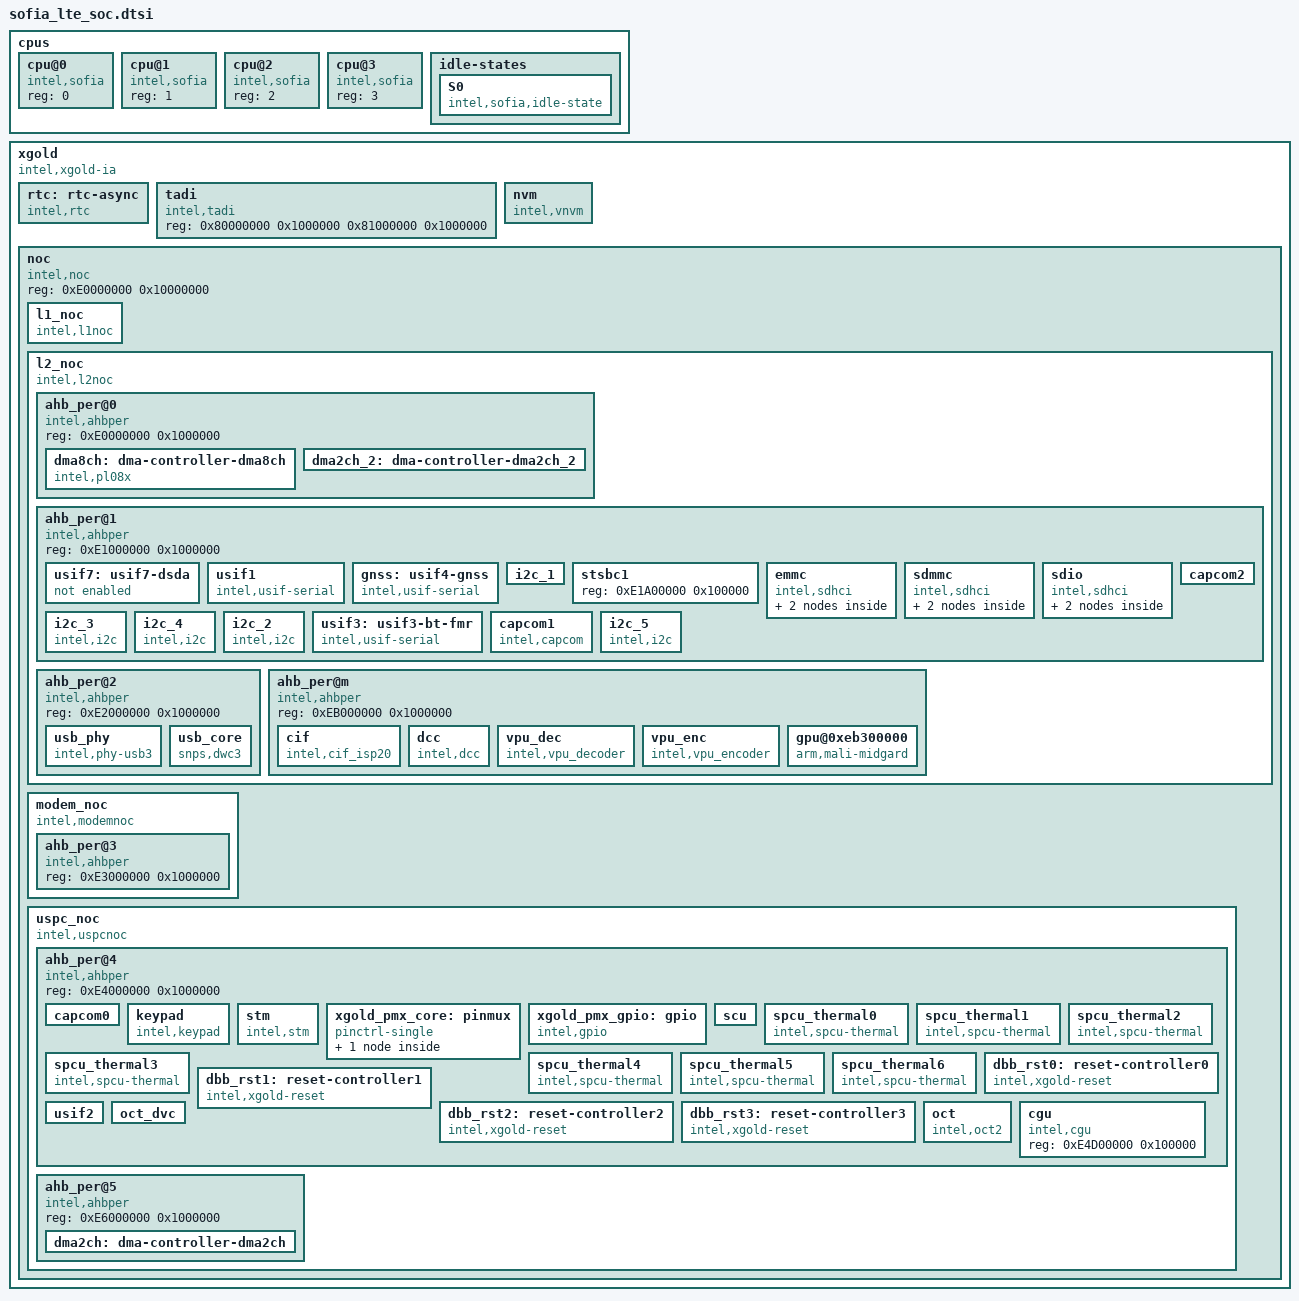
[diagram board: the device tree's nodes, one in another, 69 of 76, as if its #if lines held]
#define PREFERRED_LOCAL_APIC_USE
#define BOOST_LOCAL_APIC_USE
	cpus {
		#address-cells = <1>;
		#size-cells = <0>;
		cpu@0 {
			device_type = "cpu";
			compatible = "intel,sofia";
			reg = <0>;
		};

		cpu@1 {
			device_type = "cpu";
			compatible = "intel,sofia";
#ifdef CONFIG_X86_INTEL_SOFIA
			reg = <1>;
#else
			reg = <2>;
#endif
		};

		cpu@2 {
			device_type = "cpu";
			compatible = "intel,sofia";
			reg = <2>;
		};
		cpu@3 {
			device_type = "cpu";
			compatible = "intel,sofia";
			reg = <3>;
		};

		 idle-states {

#define CPUIDLE_FLAG_TIME_VALID	(0x01) /* is residency time measurable? */
#define CPUIDLE_FLAG_COUPLED	(0x02) /* state applies to multiple cpus */
#define CPUIDLE_FLAG_TIMER_STOP (0x04)  /* timer is stopped on this state */

			S0 {
				compatible = "intel,sofia,idle-state";
				desc = "WFE";
				power-usage = <100>;
				exit-latency = <100>;
				target-residency= <100>;
				flags = <1>;	/* CPUIDLE_FLAG_TIME_VALID */
				vmm-id = <0>;
			};
		};
	};

	xgold {
		compatible = "intel,xgold-ia", "intel,soc";
		intel,platform-dev = "uspcnoc", "noc", "l1noc", "l2noc", "modemnoc", "ahbper";
		device_type = "soc";
		#address-cells = <1>;
		#size-cells = <1>;
		ranges;
		interrupt-parent = <&pic>;
		intel,scu-phys = < &scu >;
		intel,chipid = <0x60 0x8 0x8>;
		intel,rev = <0x60 0x0 0x8>;
		intel,machine = "sofia_lte_soc-es1-svb";
#ifndef PSV_DEEP_SLEEP
		intel,nodeepsleep;
#endif
#ifndef SOFIALTE_ES2
		intel,nosteal;
#endif

		#include "xgold/sofia_lte_soc/irq-apic.dtsi"
#ifdef SOFIALTE_ES2
		#include "xgold/sofia_lte_soc/pm.dtsi"
#else
		#include "xgold/sofia_lte_soc/pm-es1.dtsi"
#endif

		/*
		 * WARNING:
		 * rtc node name must be "rtc" as it used to
		 * register wallclock callbacks during early boot
		 * To discard "rtc" from being used in wallclock
		 * callbacks, rename this node like rtc-nowc
		 */
		rtc:rtc-async {
			compatible = "intel,rtc";
			#address-cells = <0>;
			#interrupt-cells = < 1 >;
			interrupts = <0 1>;
			interrupt-names = "alarm", "completion";
			interrupt-parent = <&rtc>;
			interrupt-map = < 0 &hirq HIRQ_PMIC_SYS_ALARM IRQ_TYPE_DEFAULT
					  1 &hirq HIRQ_PMIC_RTC_STATUS IRQ_TYPE_DEFAULT >;
			intel,async = < 1 >;
			intel,base_year = < 2000 >;
		};

		tadi:tadi {
			compatible = "intel,tadi";
			#address-cells = < 0 >;
			reg = <0x80000000 0x1000000
					0x81000000 0x1000000>;
			reg-names = "trace-port", "trace-port-1";
		};
               nvm:nvm {
                       compatible = "intel,vnvm";
                       #address-cells = < 0 >;
                       intel,nb-part = < 1 >;
                       intel,part-names =
                       "/dev/block/platform/soc0/e0000000.noc/by-name/ImcPartID022";
               };

		noc {
			compatible = "intel,noc";
			#address-cells = <1>;
			#size-cells = <1>;
			ranges;
			reg = <0xE0000000 0x10000000>;

			l1_noc {
				compatible = "intel,l1noc";
				#address-cells = <1>;
				#size-cells = <1>;
				ranges;
				reg = <0xE9010000 0x4000>;

				clocks = < &clk_L1_NoC >;
				clock,rate = <400000000>;
				interrupts = < NOC_ERR_APS_L1 IRQ_TYPE_DEFAULT >, < NOC_STATALARM IRQ_TYPE_DEFAULT >;
				interrupt-names = "error", "stat_alarm";
				probe,nr = < 5 >;
				filter,nr = < 4 >;
				counter,nr = < 2 >;

				probe,offset = < 0x2000 >;

#ifdef SOFIALTE_ES2
				probe,portsel,0 = "CPU_MMIO", "CPU_PMI";
				probe,portsel,1 = "EMIC0", "EMIC1", "EMIC2";
				probe,portsel,2 = "CIF", "GPU";
				probe,portsel,3 = "DCC1", "DCC2", "VEC", "VED";
				probe,portsel,4 = "LMU";

				stat,0 = "CPU_PMI";
				stat,1 = "CPU_MMIO";
				stat,2 = "GPU";
				stat,3 = "DCC2";
				stat,4 = "VED";
				stat,5 = "VEC";
				stat,6 = "EMIC0";
				stat,7 = "EMIC1";
				stat,8 = "EMIC2";
				stat,9 = "CIF";

				intel,qos-configs = "DCC2", "GPU", "CPU1";

				intel,GPU-qos-settings = <
					0x3588 0x0      /* prio */
					0x358C 0x1      /* mode */
					0x3590 0xFFF    /* bandwidth */
					0x3594 0x3FF     /* saturation */
					0x3598 0x5>;    /* ExtCtrl */

				intel,DCC2-qos-settings = <
					0x3688 0xE      /* prio */
					0x368C 0x3      /* mode */
					0x3690 0x9F     /* bandwidth */
					0x3694 0x90     /* saturation */
					0x3698 0x5>;    /* ExtCtrl */

				intel,CPU1-qos-owner;
				intel,CPU1-qos-settings = <
					0x3708 0xF      /* prio */
					0x370C 0x0      /* mode */
					0x3710 0xFFF    /* bandwidth */
					0x3714 0x0     /* saturation */
					0x3718 0x5>;    /* ExtCtrl */

                                #include "xgold/sofia_lte_soc/NoC-es2.0.dtsi"
#else
				probe,portsel,0 = "CPU_PMI", "CPU_MMIO";
				probe,portsel,1 = "EMIC";
				probe,portsel,2 = "CIF", "GPU";
				probe,portsel,3 = "DCC1", "DCC2", "VPU";
				probe,portsel,4 = "LMU";

				stat,0 = "CPU_PMI";
				stat,1 = "CPU_MMIO";
				stat,2 = "GPU";
				stat,3 = "DCC2";
				stat,4 = "EMIC";

				intel,qos-configs = "DCC2", "GPU";
				intel,GPU-qos-owner;
				intel,GPU-qos-settings = <
					0x358C 0x1      /* GPU mode limiter */
					0x3588 0x0      /* GPU rw/wr prio 0/0 */
					0x3590 0x120    /* GPU bandwidth */
					0x3594 0x90     /* GPU saturation */
					0x3598 0x5>;    /* GPU QoSEn */

				intel,DCC2-qos-owner;
				intel,DCC2-qos-settings = <
					0x3608 0xE      /* DCC2 prio 2/3 */
					0x360C 0x3      /* DCC2 mode regulator*/
					0x3610 0x9F     /* DCC2 bandwidth */
					0x3614 0x90     /* DCC2 saturation */
					0x3618 0x5>;    /* DCC2 QoSEn */

                                #include "xgold/sofia_lte_soc/NoC.dtsi"
#endif
			};

			l2_noc {
				compatible = "intel,l2noc";
				#address-cells = <1>;
				#size-cells = <1>;
				ranges;
				reg = <0xE9014000 0x4000>;

				clocks = < &clk_L2_NoC >;
				interrupts = < NOC_ERR_APS_L2 IRQ_TYPE_DEFAULT >, < NOC_STATALARM IRQ_TYPE_DEFAULT >;
				interrupt-names = "error", "stat_alarm";
				clock,rate = <200000000>;
				probe,nr = < 5 >;
				filter,nr = < 4 >;
				counter,nr = < 2 >;

				probe,offset = < 0x2000 >;

				probe,portsel,0 = "DMA8C_1";
				probe,portsel,1 = "USB30";
				probe,portsel,2 = "SDIO", "SDMMC", "eMMC";
				probe,portsel,3 = "DMA2C_L2_1", "DMA2C_L2_2";
				probe,portsel,4 = "DMA8C_2";

				stat,0 = "eMMC";
				stat,1 = "SDIO";
				stat,2 = "SDMMC";
				stat,3 = "USB30";

				#include "xgold/sofia_lte_soc/NoC.dtsi"

				ahb_per@0 {
					compatible = "intel,ahbper";
					#address-cells = <1>;
					#size-cells = <1>;
					ranges;
					reg = <0xE0000000 0x1000000>;

					dma8ch:dma-controller-dma8ch {
						compatible = "intel,pl08x";
						reg = <0xE0100000 0x100000>;
						reg-names = "register";
						intel,dma-pl08x,buses =  < 1 1 >;
						intel,dma-pl08x,memcpy = < 3 3 2 2 1 1 1 >;
						intel,dma-pl08x,periphid = < 0x00041080 >;
						intel,mux-base = < &scu >;
						interrupts = < DMA1_ERR_INT IRQ_TYPE_DEFAULT >, < DMA1_CH0_7_INT IRQ_TYPE_DEFAULT >;
						interrupt-names = "err","chx";
						clocks = <&clk_L1_NoC>, <&clk_ahb_per0_dmac8>;
						clock-names = "clk_master1", "apb_pclk";

						#dma-cells = <1>;
						dma-channels = <15>;
						dma-requests = <21>;

						pm,class-name = "dma8ch_class";
						pm,user-name = "dmac_8ch";
						pm,state-D0 = "high_perf";
						pm,state-D3 = "disable";

						resets = < &dbb_rst2 0 >;
						reset-names = "dma";

						#include "xgold/sofia_lte_soc/dma.dtsi"
					};

					dma2ch_2:dma-controller-dma2ch_2 {
						reg = <0xE0400000 0x100000>;
						resets = < &dbb_rst2 12 >;
						reset-names = "dma2ch";
					};
				};

				ahb_per@1 {
					compatible = "intel,ahbper";
					#address-cells = <1>;
					#size-cells = <1>;
					ranges;
					reg = <0xE1000000 0x1000000>;

					usif7:usif7-dsda {
						compatible = "not enabled";
						reg = <0xE1000000 0x100000>;
						#address-cells = < 0 >;
						interrupts = < 0 >;
						interrupt-parent = <&usif7>;
						#interrupt-cells = < 1 >;
						interrupt-map = <
							0 &pic USIF7_INT IRQ_TYPE_DEFAULT
						>;
						interrupt-names = "usif-int";
						clocks = <&clk_usif7>, <&clk_ahb_per1>;
						clock-names = "kernel", "register";
						resets = < &dbb_rst2 29 >;
						reset-names = "usif";
					};

					usif1:usif1 {
						compatible = "intel,usif-serial";
						reg = <0xE1100000 0x100000>;
						#address-cells = < 0 >;
						intel,serial-port = < 0 >;
						wakeup-source;
						interrupts = < 0 1 >;
						interrupt-parent = <&usif1>;
						#interrupt-cells = < 1 >;
						interrupt-map = <
							0 &pic USIF1_INT IRQ_TYPE_DEFAULT
							1 &eint EINT_USIF1_WK XGOLD_IRQ_TYPE_EDGE_RISING
						>;
						interrupt-names = "usif-int", "wk_int";
						clocks = <&clk_usif1>, <&clk_ahb_per1>;
						clock-names = "kernel", "register";

						pm,class-name = "usif_class";
						pm,user-name = "usif1";
						pm,state-D0 = "enable_104M_hperf";
						pm,state-D3 = "disable";

						pm,runtime = "disable";
						pm,debug_rpm = "disable";
					};


					gnss:usif4-gnss {
						compatible = "intel,usif-serial";
						reg = <0xE1200000 0x100000>;
						#address-cells = < 0 >;
						intel,serial-port = < 1 >;
						wakeup-source;
						intel,usif-debug;
						intel,modem_poll_timeout = < 5 >;
						interrupts = < 0 1 >;
						interrupt-parent = <&gnss>;
						#interrupt-cells = < 1 >;
						interrupt-map = <
							0 &pic USIF4 IRQ_TYPE_DEFAULT
							1 &eint EINT_EXI15 XGOLD_IRQ_TYPE_EDGE_FALLING
						>;
						interrupt-names = "usif-int", "wk_int";
						clocks = <&clk_usif_gnss>, <&clk_ahb_per1>;
						clock-names = "kernel", "register";

						pm,class-name = "usif_class";
						pm,user-name = "usif4";
						pm,state-D0 = "enable_104M_hperf";
						pm,state-D3 = "disable";

						pm,runtime = "enable";
						pm,rpm_suspend_delay = < 15 >;
						pm,auto_suspend_enable = "enable";
						pm,gen_uevent;
					};

					i2c_1:i2c_1 {
						/* compatible = "intel,i2c"; */
						#size-cells = <1>;
						#address-cells = <0>;
						reg = <0xE1300000 0x100000>;
						clocks = <&clk_i2c1>, <&clk_ahb_per1>;
						clock-names = "clk_kernel", "clk_ahb";
						interrupts = < I2C1_INT IRQ_TYPE_DEFAULT >;
						resets = < &dbb_rst2 7 >;
						reset-names = "i2c";

						intel,i2c,b400 = < 1 54 13 0 >;
						intel,i2c,b100 = < 1 256 0 0 >;

						pm,class-name = "i2c_class";
						pm,user-name = "i2c1";
						pm,state-D0 = "enable";
						pm,state-D3 = "disable";
					};

					stsbc1:stsbc1 {
						reg = <0xE1A00000 0x100000 >;
					};

					emmc:emmc {
						compatible = "intel,sdhci";
						reg = <0xE1D00000 0x100000>;
						clocks = <&clk_emmc_kernel>, <&clk_ahb_per1>;
						clock-names = "clk_core", "clk_ahb";
						interrupts = < EMMC_INT IRQ_TYPE_DEFAULT >;
						/*setted by bootcode, capabilities register not correct*/
						/*vmmc-supply = <&vemmc>;*/
						/*vqmmc-supply = <&vdd1>;*/
#ifdef SOFIALTE_ES2
						intel,max_clock = <104000000>;
#else
						intel,max_clock = <52000000>;
#endif
						intel,min_clock = <203125>;
						intel,tap-hwbase = < &stsbc1 >;
						intel,tap_reg = < 0x40000 >;
						/* QUIRK_CAP_CLOCK_BASE_BROKEN: bit 25 + QUIRKS2_HOST_PRESET_VALUE_BROKEN: bit 3 + LED_BROKEN: bit 14*/
						intel,quirks = < 0x2000000 0x4008 >;
						bus-width = < 8 >;
						non-removable;
						intel,io-access-guest;
						pm_ctrl{
							pm,class-name = "mmcsd_volt_class";
							pm,user-name = "vemmc_volt";
							pm,state-D0 = "high_perf";
							pm,state-D0i2 = "mid_perf";
							pm,state-D3 = "disable";
						};
						clock_ctrl{
							pm,class-name = "mmcsd_clk_class";
							pm,user-name = "emmc_clk";
							pm,state-D0 = "mid_perf";
							pm,state-D0i2 = "mid_perf";
							pm,state-D3 = "disable";
						};


					};

					sdmmc:sdmmc {
						compatible = "intel,sdhci";
						#address-cells = < 0 >;
						reg = <0xE1400000 0x100000>;
					        clocks = <&clk_sdmmc_kernel>, <&clk_ahb_per1_sdmmc>;
						clock-names = "clk_core", "clk_ahb";
						interrupts = <0 1>;
						interrupt-parent = <&sdmmc>;
						#interrupt-cells = < 1 >;
						interrupt-map = <
							0 &pic SDMMC_INT IRQ_TYPE_DEFAULT
							1 &eint EINT_SDMMC_DETECT XGOLD_IRQ_TYPE_EDGE_BOTH >;
						interrupt-names = "host";
						resets = < &dbb_rst2 2 >;
						reset-names = "sdmmc";
						vqmmc-supply = <&vsdmmc>;
						intel,max_clock = <96000000>;
						intel,min_clock = <203125>;
						intel,tap-hwbase = < &stsbc1 >;
						intel,tap_reg = < 0x80000 >;
						intel,corecfg_reg = < 0x80008 >;
						intel,corecfg_val = < 0x0074C72>;
						/* BROKEN_CARD_DETECTION: bit15/
						/* QUIRK2_HOST_PRESET_VAL_BROKEN: bit3 */
						/* QUIRK2_POWER_CONTROL_BUG: bit15 */
						/* QUIRK2_HOST_EXEC_TUNING_WA: bit23 */
#ifdef SOFIALTE_ES2
						intel,quirks = < 0x0 0x80c008 >;
#else
						intel,quirks = < 0x8000 0xc008 >;
#endif
						intel,fixup = <0x1>;
						intel,io-access-guest;
						pm_ctrl{
							pm,class-name = "mmcsd_volt_class";
							pm,user-name = "sdmmc1_volt";
							pm,state-D0 = "high_perf";
							pm,state-D0i2 = "mid_perf";
							pm,state-D3 = "disable";
						};
						clock_ctrl{
							pm,class-name = "mmcsd_clk_class";
							pm,user-name = "sdmmc1_clk";
							pm,state-D0 = "mid_perf";
							pm,state-D0i2 = "mid_perf";
							pm,state-D3 = "disable";
						};

					};
					sdio:sdio {
						compatible = "intel,sdhci";
						#address-cells = < 0 >;
						reg = <0xE1700000 0x100000>;
					        clocks = <&clk_sdio_kernel>, <&clk_ahb_per1_sdio>;
						clock-names = "clk_core", "clk_ahb";
						interrupts = < SDIO_INT IRQ_TYPE_DEFAULT >;
						resets = < &dbb_rst2 3 >;
						reset-names = "sdio";
						vmmc-supply = <&wlan_ldo>;
						intel,max_clock = <200000000>;
						intel,min_clock = <203125>;
						intel,tap-hwbase = < &stsbc1 >;
						intel,tap_reg = < 0xc0000 >;
						intel,tap_reg2 = < 0xc0008 >;   /* used for feedback clock control */
						intel,corecfg_reg = < 0xc0004 0xc0008 0xc0020>;
#ifdef SOFIALTE_ES2
						/*
						 * XGOLD_DEFAULT_REGS_FIXUP	(1 << 0)
						 */
						intel,fixup = <0x1>;
						intel,corecfg_val = < 0xfe1ada20 0x0074F76 0x00001e>;
						intel,rpm_enabled = <1>;
#else
						intel,corecfg_val = < 0xfe1ada20 0x0074176 0x0000FF>;
#endif
						non-removable;
						/* QUIRK1_HOST_CLOCK_BASE_BROKEN: bit25 */
						/* QUIRK2_HOST_PRESET_VAL_BROKEN: bit3 */
						/* QUIRK2_WA_LNP: bit22 */
						/* QUIRK2_HOST_EXEC_TUNING_WA: bit23 */
						intel,quirks = < 0x2000000 0xc00008 >;
						intel,io-access-guest;
						keep-power-in-suspend;
						cap-power-off-card;
						pm_ctrl{
							pm,class-name = "mmcsd_volt_class";
							pm,user-name = "sdio_volt";
							pm,state-D0 = "high_perf";
							pm,state-D0i2 = "mid_perf";
							pm,state-D3 = "disable";
						};
						clock_ctrl{
							pm,class-name = "mmcsd_clk_class";
							pm,user-name = "sdio_clk";
							pm,state-D0 = "high_perf";
							pm,state-D0i2 = "high_perf";
							pm,state-D3 = "disable";
						};

					};


					i2c_3:i2c_3 {
						compatible = "intel,i2c";
						#size-cells = <1>;
						#address-cells = <0>;
						reg = <0xE1500000 0x100000>;
						clocks = <&clk_i2c3>, <&clk_ahb_per1>;
						clock-names = "clk_kernel", "clk_ahb";
						interrupts = < I2C3_INT IRQ_TYPE_DEFAULT >;
						resets = < &dbb_rst2 30 >;
						reset-names = "i2c";

						intel,i2c,b400 = < 1 54 13 0 >;
						intel,i2c,b100 = < 1 256 0 0 >;

						pm,class-name = "i2c_class";
						pm,user-name = "i2c3";
						pm,state-D0 = "enable";
						pm,state-D3 = "disable";
					};

					i2c_4:i2c_4 {
						compatible = "intel,i2c";
						#size-cells = <1>;
						#address-cells = <0>;
						reg = <0xE1600000 0x100000>;
						clocks = <&clk_i2c4>, <&clk_ahb_per1>;
						clock-names = "clk_kernel", "clk_ahb";
						interrupts = < I2C4 IRQ_TYPE_DEFAULT >;
						resets = < &dbb_rst2 13 >;
						reset-names = "i2c";

						intel,i2c,b400 = < 1 54 13 0 >;
						intel,i2c,b100 = < 1 256 0 0 >;

						pm,class-name = "i2c_class";
						pm,user-name = "i2c4";
						pm,state-D0 = "enable";
						pm,state-D3 = "disable";
					};

					i2c_2:i2c_2 {
						compatible = "intel,i2c";
						#size-cells = <1>;
						#address-cells = <0>;
						reg = <0xE1800000 0x100000>;
						clocks = <&clk_i2c2>, <&clk_ahb_per1>;
						clock-names = "clk_kernel", "clk_ahb";
						interrupts = < I2C2_INT IRQ_TYPE_DEFAULT >;
						resets = < &dbb_rst2 8 >;
						reset-names = "i2c";

						intel,i2c,b400 = < 1 54 13 0 >;
						intel,i2c,b100 = < 1 256 0 0 >;

						pm,class-name = "i2c_class";
						pm,user-name = "i2c2";
						pm,state-D0 = "enable";
						pm,state-D3 = "disable";
					};

					usif3:usif3-bt-fmr {
						compatible = "intel,usif-serial";
						reg = <0xE1900000 0x100000>;
						#address-cells = < 0 >;
						intel,serial-port = < 2 >;
						interrupts = < 0 1 >;
						interrupt-parent = <&usif3>;
						#interrupt-cells = < 1 >;
						interrupt-map = <
							0 &pic USIF3_INT IRQ_TYPE_DEFAULT
							1 &eint EINT_USIF3_WK XGOLD_IRQ_TYPE_EDGE_RISING
						>;
						interrupt-names = "usif-int", "wk_int";
						clocks = <&clk_usif3>, <&clk_ahb_per1>;
						clock-names = "kernel", "register";
						intel,usif-serial,datapath = "dma";
						dmas = < &dma8ch 2
							 &dma8ch 3 >;
						dma-names = "rx", "tx";
						intel,usif-serial,rx,buffer-size = < 1024 >;
						intel,ictmo-cfg = < 3000000 0x100 4000000 0x100 >; /* rate, ictmo */
						pm,class-name = "usif_class";
						pm,user-name = "usif3";
						pm,state-D0 = "enable_104M_hperf";
						pm,state-D3 = "disable";

						pm,runtime = "enable";
						pm,debug_rpm = "disable";
						pm,rpm_suspend_delay = < 300 >;
						pm,auto_suspend_enable = "enable";
					};

					capcom1:capcom1 {
						compatible = "intel,capcom";
						reg = <0xE1B00000 0x100000>;
						reg-names = "capcom-regs";
						clocks = <&clk_cap1>;
						clock-names = "clk_kernel";
						pm,class-name = "capcom_class";
						pm,user-name = "capcom1";
						pm,state-D0 = "enable"; /* enable_psv */
						pm,state-D3 = "disable"; /* disable_psv */
						resets = < &dbb_rst2 9 >;
						reset-names = "capcom";
						interrupt-controller;
						interrupt-parent = <&pic>;
						#interrupt-cells = <2>;
						interrupts =
							< CC1_CCINT0_7 IRQ_TYPE_DEFAULT >,
							< CC1_CCINT0_7 IRQ_TYPE_DEFAULT >,
							< CC1_CCINT0_7 IRQ_TYPE_DEFAULT >,
							< CC1_CCINT0_7 IRQ_TYPE_DEFAULT >,
							< CC1_CCINT0_7 IRQ_TYPE_DEFAULT >,
							< CC1_CCINT0_7 IRQ_TYPE_DEFAULT >,
							< CC1_CCINT0_7 IRQ_TYPE_DEFAULT >,
							< CC1_CCINT0_7 IRQ_TYPE_DEFAULT >;
						intel,io-access-guest;
						intel,mask,0 = < 0x84 0 1 >; /* CCx_CCINT0 */
						intel,mask,1 = < 0x84 1 1 >; /* CCx_CCINT1 */
						intel,mask,2 = < 0x84 2 1 >; /* CCx_CCINT2 */
						intel,mask,3 = < 0x84 3 1 >; /* CCx_CCINT3 */
						intel,mask,4 = < 0x84 4 1 >; /* CCx_CCINT4 */
						intel,mask,5 = < 0x84 5 1 >; /* CCx_CCINT5 */
						intel,mask,6 = < 0x84 6 1 >; /* CCx_CCINT6 */
						intel,mask,7 = < 0x84 7 1 >; /* CCx_CCINT7 */
						intel,preack,7 = <1>; /* CCx_CCINT7 */
						intel,ack,0 = < 0x8C 0 1 >; /* CCx_CCINT0 */
						intel,ack,1 = < 0x8C 1 1 >; /* CCx_CCINT1 */
						intel,ack,2 = < 0x8C 2 1 >; /* CCx_CCINT2 */
						intel,ack,3 = < 0x8C 3 1 >; /* CCx_CCINT3 */
						intel,ack,4 = < 0x8C 4 1 >; /* CCx_CCINT4 */
						intel,ack,5 = < 0x8C 5 1 >; /* CCx_CCINT5 */
						intel,ack,6 = < 0x8C 6 1 >; /* CCx_CCINT6 */
						intel,ack,7 = < 0x8C 7 1 >; /* CCx_CCINT7 */
						intel,edge,0 = < 0x14 0 3 >; /* CCx_CCINT0 */
						intel,edge,1 = < 0x14 4 3 >; /* CCx_CCINT1 */
						intel,edge,2 = < 0x14 8 3 >; /* CCx_CCINT2 */
						intel,edge,3 = < 0x14 12 3 >; /* CCx_CCINT3 */
						intel,edge,4 = < 0x18 0 3 >; /* CCx_CCINT4 */
						intel,edge,5 = < 0x18 4 3 >; /* CCx_CCINT5 */
						intel,edge,6 = < 0x18 8 3 >; /* CCx_CCINT6 */
						intel,edge,7 = < 0x18 12 3 >; /* CCx_CCINT7 */
						intel,status,0 = < 0x88 0 1 >; /* CCx_CCINT0 */
						intel,status,1 = < 0x88 1 1 >; /* CCx_CCINT1 */
						intel,status,2 = < 0x88 2 1 >; /* CCx_CCINT2 */
						intel,status,3 = < 0x88 3 1 >; /* CCx_CCINT3 */
						intel,status,4 = < 0x88 4 1 >; /* CCx_CCINT4 */
						intel,status,5 = < 0x88 5 1 >; /* CCx_CCINT5 */
						intel,status,6 = < 0x88 6 1 >; /* CCx_CCINT6 */
						intel,status,7 = < 0x88 7 1 >; /* CCx_CCINT7 */
						intel,set,0 = < 0x90 0 1 >; /* CCx_CCINT0 */
						intel,set,1 = < 0x90 1 1 >; /* CCx_CCINT1 */
						intel,set,2 = < 0x90 2 1 >; /* CCx_CCINT2 */
						intel,set,3 = < 0x90 3 1 >; /* CCx_CCINT3 */
						intel,set,4 = < 0x90 4 1 >; /* CCx_CCINT4 */
						intel,set,5 = < 0x90 5 1 >; /* CCx_CCINT5 */
						intel,set,6 = < 0x90 6 1 >; /* CCx_CCINT6 */
						intel,set,7 = < 0x90 7 1 >; /* CCx_CCINT7 */
					};

					capcom2:capcom2 {
						reg = <0xE1C00000 0x100000>;
						resets = < &dbb_rst2 10 >;
						reset-names = "capcom";
					};

					i2c_5:i2c_5 {
						compatible = "intel,i2c";
						#size-cells = <1>;
						#address-cells = <0>;
						reg = <0xE1E00000 0x100000>;
						clocks = <&clk_i2c5>, <&clk_ahb_per1>;
						clock-names = "clk_kernel", "clk_ahb";
						interrupts = < I2C5 IRQ_TYPE_DEFAULT >;
						resets = < &dbb_rst2 15 >;
						reset-names = "i2c";

						intel,i2c,b400 = < 1 54 13 0 >;
						intel,i2c,b100 = < 1 256 0 0 >;

						pm,class-name = "i2c_class";
						pm,user-name = "i2c5";
						pm,state-D0 = "enable";
						pm,state-D3 = "disable";
					};
				};

				ahb_per@2 {
					compatible = "intel,ahbper";
					#address-cells = <1>;
					#size-cells = <1>;
					ranges;
					reg = <0xE2000000 0x1000000>;

					usb_phy:usb_phy {
						compatible = "intel,phy-usb3";
						#size-cells = < 1 >;
						#address-cells = < 0 >;
						/* SCU USB for PHY config, LMU TRB for EBC config */
						reg = < 0xE4900000 0x1000 >, < 0xE9940000 0x100 >;
						reg-names = "scu_usb", "lmu_usb";

						interrupts = < 0 >;
						interrupt-parent = < &usb_phy >;
						#interrupt-cells = < 1 >;
						/* USB_RESUME IRQ with interrupt number=0, interrupt parent = eint, EDGE RISING */
						interrupt-map = < 0 &eint EINT_USB_HS_RESUME XGOLD_IRQ_TYPE_EDGE_RISING >;
						interrupt-names = "usb_resume";

						resets = < &dbb_rst2 23 >, < &dbb_rst2 25 >;
						reset-names = "usb_susp", "usb_core";

						pm,class-name = "usb";
						pm,user-name = "usb";

						scu_usb_ss_trim = < 0x242486ed 0x2506a862 0x2104>;

						iso-supply = <&vdd_usb_ss_phy>;
						phy-supply = <&vusb>;
						core-supply = <&vdd_usb_30_pen>;
						digital-supply = <&ldo_usb_30>;

						clocks = <&clk_usb_ss>, <&clk_ahb_per2>;
						clock-names = "clk_kernel", "clk_bus";

					};

					usb_core:usb_core {
						compatible = "snps,dwc3";
						#size-cells = < 1 >;
						#address-cells = < 0 >;
						reg= < 0xE2D00000 0x80000 >;
						interrupts = < USB_INT IRQ_TYPE_DEFAULT >;
						/* use same PHY for USB 2.0 and 3.0 */
						usb-phy = < &usb_phy >, < &usb_phy >;
						tx-fifo-resize;
					};
				};
				ahb_per@m {
					compatible = "intel,ahbper";
					#address-cells = <1>;
					#size-cells = <1>;
					ranges;
					reg = <0xEB000000 0x1000000>;

#ifndef RECOVERY_KERNEL
					cif:cif{
						compatible = "intel,cif_isp20";
						reg = <0xEB000000 0x100000>;
						reg-names = "register";
						interrupts = <
							CIF_ISP_INT IRQ_TYPE_DEFAULT
							CIF_MI_INT IRQ_TYPE_DEFAULT
							CIF_MIPI_INT IRQ_TYPE_DEFAULT
							CIF_JPEG_STAT_INT IRQ_TYPE_DEFAULT
							CIF_JPEG_ERR_INT IRQ_TYPE_DEFAULT>;
						interrupt-names = "CIF_ISP20_ISP_IRQ", "CIF_ISP20_MI_IRQ", "CIF_ISP20_MIPI_IRQ", "CIF_ISP20_JPE_STATUS_IRQ", "CIF_ISP20_JPE_ERROR_IRQ";
						pm,class-name = "cif_class";
						pm,user-name = "cif";
						pm,state-D0 = "high_perf";
						pm,state-D3 = "disable";

						vdd_csi_phy_primary-supply = <&vdd_csi_phy_primary>;
						vdd_csi_phy_aux-supply  = <&vdd_csi_phy_aux>;
						vmipi-supply = <&vmipi>;
						vdd_cif_pon-supply = <&vdd_cif_pon>;
						ldo_pll_mipi-supply = <&ldo_pll_mipi>;
						intel,supply = "vdd_csi_phy_primary", "vdd_csi_phy_aux", "vmipi", "vdd_cif_pon", "ldo_pll_mipi";
#ifdef SOFIALTE_ES2
						clocks = <&clk_mm_cifkernel>, <&clk_mm_cifmaster>, <&clk_ahb_perm>, <&MUX_OUT_1>;
#else
						clocks = <&clk_mm_cifkernel>, <&clk_mm_cifkernel>, <&clk_ahb_perm>, <&MUX_OUT_1>;
#endif
						clock-names = "clk_kernel", "clk_master", "clk_slave", "clk_sensor";

					};
#endif

					dcc:dcc {
						compatible = "intel,dcc";
						#address-cells = < 0 >;
						reg = <0xEB100000 0x10000
								0xEB110000 0xF0000>;
						reg-names = "registers";
						clocks = <&clk_mm_dcc>, <&clk_ahb_perm>, <&clk_L1_NoC>;
						clock-names = "clk_kernel", "clk_ahb", "clk_master";
						interrupts = < 0 1 2 >;
						interrupt-parent = <&dcc>;
						#interrupt-cells = < 1 >;
						interrupt-map = <
							0 &pic DIF_ERR_INT IRQ_TYPE_DEFAULT
							1 &pic DCC_CMD_INT IRQ_TYPE_DEFAULT
							2 &pic DCC_FRAME_INT IRQ_TYPE_DEFAULT >;
						interrupt-names = "err", "cmd", "frame";

						pm,class-name = "dcc_class";
						pm,user-name = "dcc";
						pm,state-D0 = "high_perf";
						pm,state-D1 = "mid_perf";
						pm,state-D2 = "low_perf";
						pm,state-D3 = "disable";
						vmipi-supply = <&vmipi>;
						intel,vmipi-voltage = <2850000>;
						pll_mipi-supply = <&ldo_pll_mipi>;
						vdd_dsi_phy-supply = < &vdd_dsi_phy >;
						vdd_dif-supply = < &vdd_dif >;
						vdd_dcc_pon-supply = < &vdd_dcc_pon >;
						intel,supply = "vmipi", "pll_mipi","vdd_dsi_phy","vdd_dif","vdd_dcc_pon";

						intel,dcc-clkrate = <416000000>;
						intel,dcc-gpio-reset = <&xgold_pmx_gpio 15 0 >;
						resets = < &dbb_rst0 0 >;
						reset-names = "dcc";
					};

					vpu_dec {
						compatible = "intel,vpu_decoder";
						reg = < 0x00000000 0x000 >;
						interrupt-names = "vpu_dec";
						interrupts = < VID_HINT_DEC IRQ_TYPE_DEFAULT  >;

						pm,class-name = "vpu_dec_class";
						pm,user-name = "video_dec";
						pm,state-D3 = "disable";
						pm,state-D0 = "high_perf"; /*"ultra_high_perf"*/

						video-supply = <&vdd_vpu_pon>;
						clocks = <&clk_mm_video>, <&clk_mm_video>, <&clk_ahb_perm>;
						clock-names = "clk_kernel", "clk_master", "clk_slave";

						resets = < &dbb_rst1 24 >;
						reset-names = "vpu_dec";

						/*vvpu-secvm;*/
					};
					vpu_enc {
						compatible = "intel,vpu_encoder";
						reg = < 0x00000000 0x000 >;
						interrupt-names = "vpu_enc";
						interrupts = < VID_HINT_ENC IRQ_TYPE_DEFAULT >;

						pm,class-name = "vpu_enc_class";
						pm,user-name = "video_enc";
						pm,state-D3 = "disable";
						pm,state-D0 = "high_perf"; /*"ultra_high_perf"*/

						video-supply = <&vdd_vpu_pon>;
						clocks = <&clk_mm_video>, <&clk_mm_video>, <&clk_ahb_perm>;
						clock-names = "clk_kernel", "clk_master", "clk_slave";

						resets = < &dbb_rst1 24 >;
						reset-names = "vpu_enc";
					};


#ifdef SOFIALTE_ES2
					gpu@0xeb300000 {
						compatible = "arm,mali-midgard";
						reg = <0xeb300000 0x10000>;
						interrupts = <GPU_INT IRQ_TYPE_DEFAULT>,
							<GPU_INT IRQ_TYPE_DEFAULT>,
							<GPU_INT IRQ_TYPE_DEFAULT>;
						interrupt-names = "JOB", "MMU", "GPU";
						clocks = <&clk_mm_gpu>, <&clk_ahb_perm>;
						clock-names = "clk_mali", "clk_ahb";
						gpu-supply = <&vdd_gpu_pon>;

						pm,class-name = "gpu_class";
						pm,user-name = "gpu";
						pm,state-D0 = "high_perf";
						pm,state-D0i2 = "mid_perf";
						pm,state-D0i3 = "low_perf";
						pm,state-D3 = "disable";

						resets = < &dbb_rst2 16 >;
						reset-names = "gpu";
					};
#else /* SOFIALTE_ES1 */
					gpu@EB300000 {
						compatible = "arm,mali-400", "arm,mali-utgard";
						reg = <0xEB300000 0x100000>;
						/* Mali400 MP2 no PMU */
						interrupts = < GPU_INT IRQ_TYPE_DEFAULT >, < GPU_INT IRQ_TYPE_DEFAULT >,
							< GPU_INT IRQ_TYPE_DEFAULT >, < GPU_INT IRQ_TYPE_DEFAULT >,
							< GPU_INT IRQ_TYPE_DEFAULT >, < GPU_INT IRQ_TYPE_DEFAULT >;
						interrupt-names = "IRQGP", "IRQGPMMU", "IRQPP0", "IRQPPMMU0", "IRQPP1", "IRQPPMMU1";

						dvfs_off;
						dvfs_clock_config = < 312 1000 >, < 416 2000 >, < 480 3000 >;

						clocks = <&clk_mm_gpu>, <&clk_ahb_perm>;
						clock-names = "clk_kernel", "clk_ahb";
						gpu-supply = <&vdd_gpu_pon>;

						pm,class-name = "gpu_class";
						pm,user-name = "gpu";
						pm,state-D0 = "high_perf";
						pm,state-D0i2 = "mid_perf";
						pm,state-D0i3 = "low_perf";
						pm,state-D3 = "disable";

						resets = < &dbb_rst2 16 >;
						reset-names = "gpu";
					};
#endif
				};
			};
			modem_noc {
				compatible = "intel,modemnoc";
				#address-cells = <1>;
				#size-cells = <1>;
				ranges;
				reg = <0xE9018000 0x4000>;
				interrupts = < NOC_ERR_APS_MAC IRQ_TYPE_DEFAULT >, < NOC_STATALARM IRQ_TYPE_DEFAULT >;
				interrupt-names = "error", "stat_alarm";
				clock,rate = <200000000>;
				probe,nr = < 3 >;
				filter,nr = < 4 >;
				counter,nr = < 2 >;

				probe,offset = < 0x2000 >;

				probe,portsel,0 = "DL_ECYPHER0", "DL_ECYPHER1", "DL_EMACPHY", "DL_EMACPHY", "MACPHY_TILE6", "UL_ECYPHER0", "UL_ECYPHER1", "UL_EMACPHY";
				probe,portsel,1 = "L1CTRL_3G";
				probe,portsel,2 = "L1CTRL_LTE", "LTE_TEST1", "LTE_TEST2";

				#include "xgold/sofia_lte_soc/NoC.dtsi"
				ahb_per@3 {
					compatible = "intel,ahbper";
					#address-cells = <1>;
					#size-cells = <1>;
					ranges;
					reg = <0xE3000000 0x1000000>;

					#include "xgold/sofia_lte_soc/dsp-audio-f.dtsi"
					#include "xgold/sofia_lte_soc/dsp-audio-s.dtsi"

				};
			};
			uspc_noc {
				compatible = "intel,uspcnoc";
				#address-cells = <1>;
				#size-cells = <1>;
				ranges;
				/* FIXME: Add HW resources */

				ahb_per@4 {
					compatible = "intel,ahbper";
					#address-cells = <1>;
					#size-cells = <1>;
					ranges;
					reg = <0xE4000000 0x1000000>;

					capcom0:capcom0 {
						reg = <0xE4000000 0x100000>;
						resets = < &dbb_rst1 5 >;
						reset-names = "capcom";
					};

					keypad:keypad {
						compatible = "intel,keypad";
						#address-cells = < 0 >;
						reg = <0xE4200000 0x100000>;
						interrupts = < 0 >;
						interrupt-parent = < &keypad>;
						#interrupt-cells = < 1 >;
						interrupt-map = <
							/* KPINT */ 0 &pic KPD_INT IRQ_TYPE_DEFAULT
						>;
						interrupt-names = "kpint";
						clocks = <&clk_ahb_per4>;
						clock-names = "clk_ahb";
						pm,class-name = "xgold_kpd_class";
						pm,user-name = "kpd";
						pm,state-D0 = "enable";
						pm,state-D3 = "disable";
					};

					stm:stm {
						compatible = "intel,stm";
						reg = <0xE4500000 0x100000>;
						clocks = <&clk_26m_stm>;
						clock-names = "kernel";
						interrupts = < STM_INT0 IRQ_TYPE_DEFAULT >, < STM_INT1 IRQ_TYPE_DEFAULT>;
						intel,stm,src,rating = <50>;
						intel,stm,cpumask = <0x3>;
						intel,stm,evt,rating = <50>;
						intel,stm,rate = <26000000>;
						intel,evt,min-ns = <38000>;
						intel,evt,max-ns = <1000000000>;

					};

					xgold_pmx_core:pinmux {
						compatible = "pinctrl-single";
#ifdef SOFIALTE_ES2
						reg = <0xE4800000 0xa48>;
#else
						reg = <0xE4800000 0x80a40>;
#endif
						#address-cells = <1>;
						#size-cells = <1>;
						ranges;
						#gpio-range-cells = <3>;
						pinctrl-single,register-width = <32>;
#ifdef SOFIALTE_ES2
						pinctrl-single,first-pin-offset = <0x200>;
#else
						pinctrl-single,first-pin-offset = <0x80200>;
#endif
						pinctrl-single,function-mask = <0xfffff>;

						range: gpio-range {
							#pinctrl-single,gpio-range-cells = <3>;
						};
					};

					xgold_pmx_gpio:gpio {
						compatible = "intel,gpio";
						#gpio-cells = <2>;
						reg = <0xE4800000 0x100000>;
						gpio-controller;
						gpio-ranges = <&xgold_pmx_core 0 0 145>;
						intel,gpio-direction-out = < 1 >;
#ifdef SOFIALTE_ES2
						intel,gpio-direction = < 0x200 10 1>;
						intel,gpio-output = < 0x200 9 1 >;
						intel,gpio-input = < 0x800 9 1 >;
#else
						intel,gpio-direction = < 0x80200 10 1>;
						intel,gpio-output = < 0x80200 9 1 >;
						intel,gpio-input = < 0x80800 9 1 >;
#endif
						intel,gpiochip-base = <0>;
						intel,gpiochip-id = <0>;
						intel,gpiochip-num = <145>;
					};




					scu:scu{
						reg = <0xE4900000 0x10000
								0xE4910000 0x10000
								0xE4920000 0x10000>;
						reg-names = "scu", "scu_hw", "scu_idc";
					};

					spcu_thermal0{
						compatible = "intel,spcu-thermal";
						reg = <0xE4D00000 0x100000>;
						interrupt-parent = <&hirq>;
						interrupts = <HIRQ_SPCU_THERM0_LOW IRQ_TYPE_DEFAULT>,
							     <HIRQ_SPCU_THERM0_HIGH IRQ_TYPE_DEFAULT>;
						interrupt-names = "TLOW", "THIGH";
						intel,thermal-type = "coretemp0";
						intel,config-set_hw = <1>;
						intel,thermal-id = <0>;
						intel,config-reg = <0x2E0>;
						intel,ctrl-reg = <0x2E4>;
						intel,stat-reg = <0xA0060>;
					};

					spcu_thermal1{
						compatible = "intel,spcu-thermal";
						reg = <0xE4D00000 0x100000>;
						interrupt-parent = <&hirq>;
						interrupts = <HIRQ_SPCU_THERM1_LOW IRQ_TYPE_DEFAULT>,
							     <HIRQ_SPCU_THERM1_HIGH IRQ_TYPE_DEFAULT>;
						interrupt-names = "TLOW", "THIGH";
						intel,thermal-type = "coretemp1";
						intel,config-set_hw = <1>;
						intel,thermal-id = <1>;
						intel,config-reg = <0x2E8>;
						intel,ctrl-reg = <0x2EC>;
						intel,stat-reg = <0xA0064>;
					};

					spcu_thermal2{
						compatible = "intel,spcu-thermal";
						reg = <0xE4D00000 0x100000>;
						interrupt-parent = <&hirq>;
						interrupts = <HIRQ_SPCU_THERM2_LOW IRQ_TYPE_DEFAULT>,
							     <HIRQ_SPCU_THERM2_HIGH IRQ_TYPE_DEFAULT>;
						interrupt-names = "TLOW", "THIGH";
						intel,thermal-type = "coretemp2";
						intel,config-set_hw = <1>;
						intel,thermal-id = <2>;
						intel,config-reg = <0x2F4>;
						intel,ctrl-reg = <0x2F8>;
						intel,stat-reg = <0xA0068>;
					};

					spcu_thermal3{
						compatible = "intel,spcu-thermal";
						reg = <0xE4D00000 0x100000>;
						interrupt-parent = <&hirq>;
						interrupts = <HIRQ_SPCU_THERM3_LOW IRQ_TYPE_DEFAULT>,
							     <HIRQ_SPCU_THERM3_HIGH IRQ_TYPE_DEFAULT>;
						interrupt-names = "TLOW", "THIGH";
						intel,config-set_hw = <1>;
						intel,thermal-type = "coretemp3";
						intel,thermal-id = <3>;
						intel,config-reg = <0x2FC>;
						intel,ctrl-reg = <0x300>;
						intel,stat-reg = <0xA006C>;
					};

					spcu_thermal4{
						compatible = "intel,spcu-thermal";
						reg = <0xE4D00000 0x100000>;
						interrupt-parent = <&hirq>;
						interrupts = <HIRQ_SPCU_THERM4_LOW IRQ_TYPE_DEFAULT>,
							     <HIRQ_SPCU_THERM4_HIGH IRQ_TYPE_DEFAULT>;
						interrupt-names = "TLOW", "THIGH";
						intel,config-set_hw = <1>;
						intel,thermal-type = "LTE";
						intel,thermal-id = <4>;
						intel,config-reg = <0x304>;
						intel,ctrl-reg = <0x308>;
						intel,stat-reg = <0xA007C>;
					};

					spcu_thermal5{
						compatible = "intel,spcu-thermal";
						reg = <0xE4D00000 0x100000>;
						interrupt-parent = <&hirq>;
						interrupts = <HIRQ_SPCU_THERM5_LOW IRQ_TYPE_DEFAULT>,
							     <HIRQ_SPCU_THERM5_HIGH IRQ_TYPE_DEFAULT>;
						interrupt-names = "TLOW", "THIGH";
						intel,config-set_hw = <1>;
						intel,thermal-type = "SPCU";
						intel,thermal-id = <5>;
						intel,config-reg = <0x30C>;
						intel,ctrl-reg = <0x310>;
						intel,stat-reg = <0xA0080>;
					};

					spcu_thermal6{
						compatible = "intel,spcu-thermal";
						reg = <0xE4D00000 0x100000>;
						interrupt-parent = <&hirq>;
						interrupts = <HIRQ_SPCU_THERM6_LOW IRQ_TYPE_DEFAULT>,
							     <HIRQ_SPCU_THERM6_HIGH IRQ_TYPE_DEFAULT>;
						interrupt-names = "TLOW", "THIGH";
						intel,config-set_hw = <1>;
						intel,thermal-type = "GPU";
						intel,thermal-id = <6>;
						intel,config-reg = <0x314>;
						intel,ctrl-reg = <0x318>;
						intel,stat-reg = <0xA0084>;
					};

					dbb_rst0:reset-controller0 {
						compatible = "intel,xgold-reset";
						reg = <0xE4900218 0x4>;
						#reset-cells = <1>;
						intel,reset-rw = <0>;
						intel,io-access-guest;
					};

					dbb_rst1:reset-controller1 {
						compatible = "intel,xgold-reset";
						reg = <0xE490021C 0x4>;
						#reset-cells = <1>;
						intel,reset-rw = <0>;
						intel,io-access-guest;
					};

					dbb_rst2:reset-controller2 {
						compatible = "intel,xgold-reset";
						reg = <0xE4900220 0x4>;
						#reset-cells = <1>;
						intel,reset-rw = <0>;
						intel,io-access-guest;
					};

					dbb_rst3:reset-controller3 {
						compatible = "intel,xgold-reset";
						reg = <0xE4900224 0x4>;
						#reset-cells = <1>;
						intel,reset-rw = <0>;
						intel,io-access-guest;
					};

					usif2:usif2 {
						reg = <0xE4A00000 0x100000>;
						resets = < &dbb_rst1 10 >;
						reset-names = "usif";
						clocks = <&clk_usif2>, <&clk_ahb_per4>;
						clock-names = "kernel", "register";
					};
					oct:oct {
#ifdef SOFIALTE_ES2
						compatible = "intel,oct2";
#else
						compatible = "intel,oct";
#endif
						reg = <0xE4B40000 0x20000>;
						reg-names = "oct-registers";
						interrupts = <OCT_INT IRQ_TYPE_DEFAULT>;
						interrupt-names = "OCT_INT";
						pm,user-name = "st_oct";
						pm,class-name = "trace_pm_class";
						pm,state-D0 = "enable";
						pm,state-D3 = "disable";
					};
					oct_dvc:oct_dvc {
						reg = <0xE4B60000 0x20000>;
						reg-names = "oct-dvc-registers";
						pm,user-name = "st_oct_dvc";
						pm,class-name = "trace_pm_class";
						pm,state-D0 = "enable";
						pm,state-D3 = "disable";
					};
					cgu:cgu {
						compatible = "intel,cgu";
						reg = <0xE4D00000 0x100000>;
					};
				};
				ahb_per@5 {
					compatible = "intel,ahbper";
					#address-cells = <1>;
					#size-cells = <1>;
					ranges;
					reg = <0xE6000000 0x1000000>;

					dma2ch:dma-controller-dma2ch {
						reg = <0xE6100000 0x100000>;
						resets = < &dbb_rst1 16 >;
						reset-names = "dma2ch";
					};
				};
			};
		};
	};
